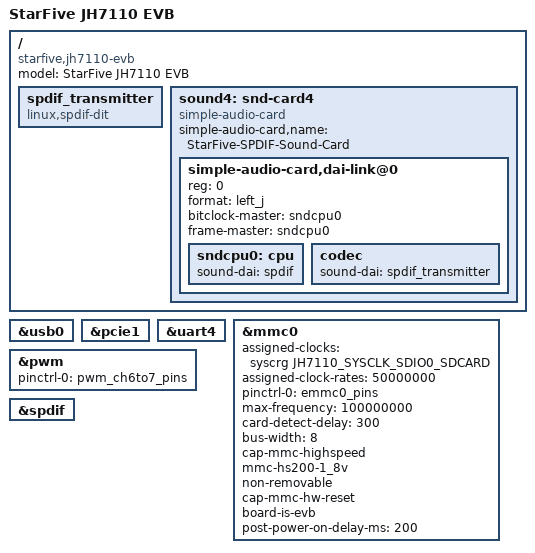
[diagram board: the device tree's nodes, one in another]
// SPDX-License-Identifier: GPL-2.0 OR MIT
/*
 * Copyright (C) 2022 StarFive Technology Co., Ltd.
 */

/dts-v1/;
#include "jh7110-evb.dtsi"

/ {
	model = "StarFive JH7110 EVB";
	compatible = "starfive,jh7110-evb", "starfive,jh7110";

	spdif_transmitter: spdif_transmitter {
		compatible = "linux,spdif-dit";
		#sound-dai-cells = <0>;
	};

	sound4: snd-card4 {
		compatible = "simple-audio-card";
		#address-cells = <1>;
		#size-cells = <0>;

		simple-audio-card,name = "StarFive-SPDIF-Sound-Card";
		simple-audio-card,dai-link@0 {
			reg = <0>;
			format = "left_j";
			bitclock-master = <&sndcpu0>;
			frame-master = <&sndcpu0>;

			sndcpu0: cpu {
				sound-dai = <&spdif>;
			};

			codec {
				sound-dai = <&spdif_transmitter>;
			};
		};
	};
};

&usb0 {
	status = "okay";
};

&pcie1 {
	status = "okay";
};

&uart4 {
	status = "okay";
};

&mmc0 {
	assigned-clocks = <&syscrg JH7110_SYSCLK_SDIO0_SDCARD>;
	assigned-clock-rates = <50000000>;
	pinctrl-names = "default";
	pinctrl-0 = <&emmc0_pins>;
	max-frequency = <100000000>;
	card-detect-delay = <300>;
	bus-width = <8>;
	cap-mmc-highspeed;
	mmc-hs200-1_8v;
	non-removable;
	cap-mmc-hw-reset;
	board-is-evb;
	post-power-on-delay-ms = <200>;
	status = "okay";
};

&pwm {
	pinctrl-names = "default";
	pinctrl-0 = <&pwm_ch6to7_pins>;
	status = "okay";
};

&spdif {
	status = "okay";
};
